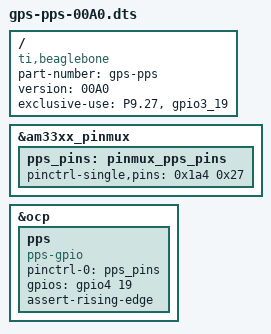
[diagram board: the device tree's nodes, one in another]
/dts-v1/;
/plugin/;

/ {
  compatible = "ti,beaglebone", "ti,beaglebone-black";

  part-number = "gps-pps";
  version = "00A0";

  exclusive-use = "P9.27", "gpio3_19";

  fragment@0 {
    target = <&am33xx_pinmux>;
    __overlay__ {
      pps_pins: pinmux_pps_pins {
        pinctrl-single,pins = <0x1a4 0x27>;
      };
    };
  };

  fragment@1 {
    target = <&ocp>;

    __overlay__ {
      pps {
        compatible = "pps-gpio";
        status = "okay";
        pinctrl-names = "default";
        pinctrl-0 = <&pps_pins>;
        gpios = <&gpio4 19 0>;
        assert-rising-edge;
      };
    };
  };
};
